# ipro6s register map
Vendor: intelpro; Series: IPRO6S
CPU: ipro6s, little endian
Registers are 32-bit, read-write, reset 0x0 unless marked. A register's access mark holds for its fields unless they carry their own. Offsets are from the block's base; [hi:lo] are bit positions; {n}, {i} and the like mark numbered series.

## I2C0
Base 0x3000E000
Same registers: I2C1 0x3000F000
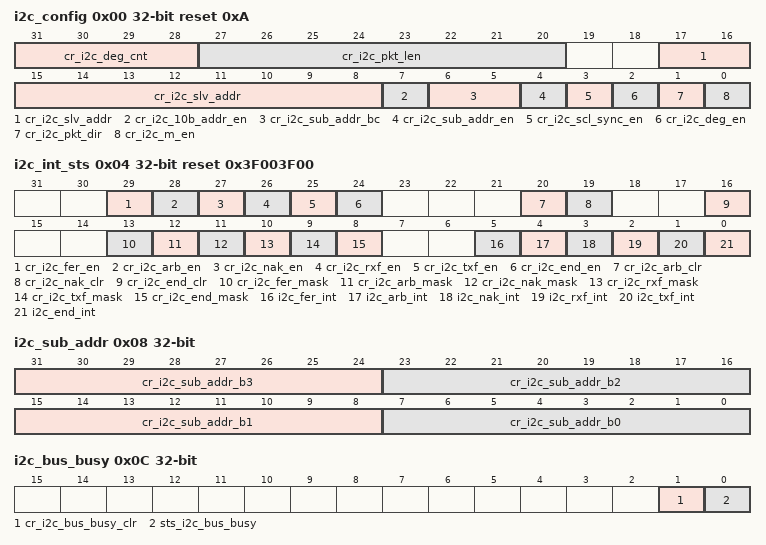
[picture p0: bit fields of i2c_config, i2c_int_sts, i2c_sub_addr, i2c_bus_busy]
0x00 i2c_config reset 0xA
  [31:28] cr_i2c_deg_cnt — De-glitch function cycle count
  [27:20] cr_i2c_pkt_len — Packet length (unit: byte)
  [17:8] cr_i2c_slv_addr — Slave address for I2C transaction (target address)
  [7] cr_i2c_10b_addr_en — Slave address 10-bit mode enable
  [6:5] cr_i2c_sub_addr_bc — Sub-address field byte count 2'd0: 1-byte, 2'd1: 2-byte, 2'd2: 3-byte, 2'd3: 4-byte
  [4] cr_i2c_sub_addr_en — Enable signal of I2C sub-address field
  [3] cr_i2c_scl_sync_en — Enable signal of I2C SCL synchronization, should be enabled to support Multi-Master and Clock-Stretching (Normally should not be turned-off)
  [2] cr_i2c_deg_en — Enable signal of I2C input de-glitch function (for all input pins)
  [1] cr_i2c_pkt_dir — Transfer direction of the packet 1'b0: Write; 1'b1: Read
  [0] cr_i2c_m_en — Enable signal of I2C Master function Asserting this bit will trigger the transaction, and should be de-asserted after finish
0x04 i2c_int_sts reset 0x3F003F00 (reset mask 0x3F3F3F00)
  [29] cr_i2c_fer_en — Interrupt enable of i2c_fer_int
  [28] cr_i2c_arb_en — Interrupt enable of i2c_arb_int
  [27] cr_i2c_nak_en — Interrupt enable of i2c_nak_int
  [26] cr_i2c_rxf_en — Interrupt enable of i2c_rxf_int
  [25] cr_i2c_txf_en — Interrupt enable of i2c_txf_int
  [24] cr_i2c_end_en — Interrupt enable of i2c_end_int
  [20] cr_i2c_arb_clr wo — Interrupt clear of i2c_arb_int
  [19] cr_i2c_nak_clr wo — Interrupt clear of i2c_nak_int
  [16] cr_i2c_end_clr wo — Interrupt clear of i2c_end_int
  [13] cr_i2c_fer_mask — Interrupt mask of i2c_fer_int
  [12] cr_i2c_arb_mask — Interrupt mask of i2c_arb_int
  [11] cr_i2c_nak_mask — Interrupt mask of i2c_nak_int
  [10] cr_i2c_rxf_mask — Interrupt mask of i2c_rxf_int
  [9] cr_i2c_txf_mask — Interrupt mask of i2c_txf_int
  [8] cr_i2c_end_mask — Interrupt mask of i2c_end_int
  [5] i2c_fer_int ro — I2C TX/RX FIFO error interrupt, auto-cleared when FIFO overflow/underflow error flag is cleared
  [4] i2c_arb_int ro — I2C arbitration lost interrupt
  [3] i2c_nak_int ro — I2C NACK-received interrupt
  [2] i2c_rxf_int ro — I2C RX FIFO ready (rx_fifo_cnt > rx_fifo_th) interrupt, auto-cleared when data is popped
  [1] i2c_txf_int ro — I2C TX FIFO ready (tx_fifo_cnt > tx_fifo_th) interrupt, auto-cleared when data is pushed
  [0] i2c_end_int ro — I2C transfer end interrupt
0x08 i2c_sub_addr
  [31:24] cr_i2c_sub_addr_b3 — I2C sub-address field - byte[3]
  [23:16] cr_i2c_sub_addr_b2 — I2C sub-address field - byte[2]
  [15:8] cr_i2c_sub_addr_b1 — I2C sub-address field - byte[1]
  [7:0] cr_i2c_sub_addr_b0 — I2C sub-address field - byte[0] (sub-address starts from this byte)
0x0C i2c_bus_busy (reset mask 0x2)
  [1] cr_i2c_bus_busy_clr wo — Clear signal of bus_busy status, not for normal usage (in case I2C bus hangs)
  [0] sts_i2c_bus_busy ro — Indicator of I2C bus busy
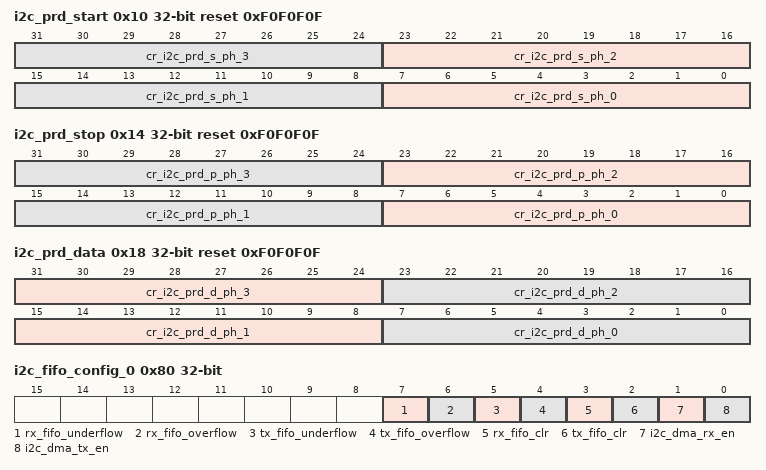
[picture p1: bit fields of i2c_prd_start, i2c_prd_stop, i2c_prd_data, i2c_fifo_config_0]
0x10 i2c_prd_start reset 0xF0F0F0F
  [8n+7:8n] cr_i2c_prd_s_ph_{n} (n=0..3) — Length of START condition phase {n}
0x14 i2c_prd_stop reset 0xF0F0F0F
  [8n+7:8n] cr_i2c_prd_p_ph_{n} (n=0..3) — Length of STOP condition phase {n}
0x18 i2c_prd_data reset 0xF0F0F0F
  [31:24] cr_i2c_prd_d_ph_3 — Length of DATA phase 3
  [23:16] cr_i2c_prd_d_ph_2 — Length of DATA phase 2
  [15:8] cr_i2c_prd_d_ph_1 — Length of DATA phase 1 Note: This value should not be set to 8'd0, adjust source clock rate instead if higher I2C clock rate is required
  [7:0] cr_i2c_prd_d_ph_0 — Length of DATA phase 0
0x80 i2c_fifo_config_0 (reset mask 0xF)
  [7] rx_fifo_underflow ro — Underflow flag of RX FIFO, can be cleared by rx_fifo_clr
  [6] rx_fifo_overflow ro — Overflow flag of RX FIFO, can be cleared by rx_fifo_clr
  [5] tx_fifo_underflow ro — Underflow flag of TX FIFO, can be cleared by tx_fifo_clr
  [4] tx_fifo_overflow ro — Overflow flag of TX FIFO, can be cleared by tx_fifo_clr
  [3] rx_fifo_clr wo — Clear signal of RX FIFO
  [2] tx_fifo_clr wo — Clear signal of TX FIFO
  [1] i2c_dma_rx_en — Enable signal of dma_rx_req/ack interface
  [0] i2c_dma_tx_en — Enable signal of dma_tx_req/ack interface
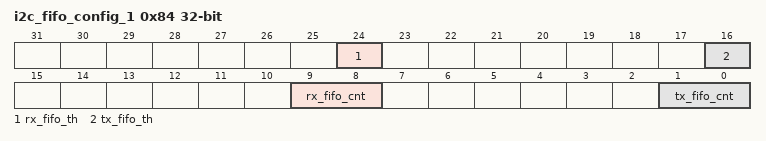
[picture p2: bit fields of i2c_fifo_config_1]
0x84 i2c_fifo_config_1 (reset mask 0x1010000)
  [24] rx_fifo_th — RX FIFO threshold, dma_rx_req will not be asserted if rx_fifo_cnt is less than this value
  [16] tx_fifo_th — TX FIFO threshold, dma_tx_req will not be asserted if tx_fifo_cnt is less than this value
  [9:8] rx_fifo_cnt ro — RX FIFO available count
  [1:0] tx_fifo_cnt ro — TX FIFO available count
0x88 i2c_fifo_wdata
  [31:0] i2c_fifo_wdata wo
0x8C i2c_fifo_rdata reset not defined
  [31:0] i2c_fifo_rdata ro
